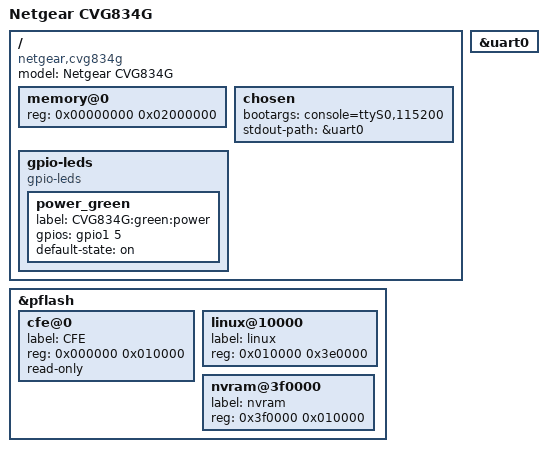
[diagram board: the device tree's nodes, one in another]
/dts-v1/;

#include "bcm3368.dtsi"

#include <dt-bindings/input/input.h>

/ {
	model = "Netgear CVG834G";
	compatible = "netgear,cvg834g", "brcm,bcm3368";

	memory@0 {
		device_type = "memory";
		reg = <0x00000000 0x02000000>;
	};

	chosen {
		bootargs = "console=ttyS0,115200";
		stdout-path = &uart0;
	};

	gpio-leds {
		compatible = "gpio-leds";

		power_green {
			label = "CVG834G:green:power";
			gpios = <&gpio1 5 0>;
			default-state = "on";
		};
	};
};

&pflash {
	status = "ok";

	cfe@0 {
		label = "CFE";
		reg = <0x000000 0x010000>;
		read-only;
	};
	linux@10000 {
		label = "linux";
		reg = <0x010000 0x3e0000>;
	};
	nvram@3f0000 {
		label = "nvram";
		reg = <0x3f0000 0x010000>;
	};
};

&uart0 {
	status = "ok";
};
